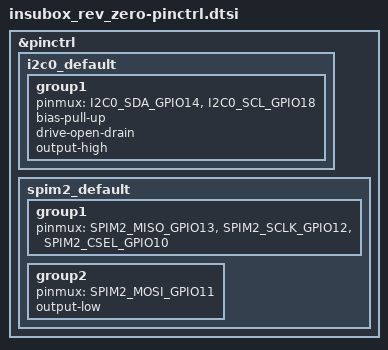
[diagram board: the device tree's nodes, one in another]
/*
 * Copyright (c) 2024 Espressif Systems (Shanghai) Co., Ltd.
 *
 * SPDX-License-Identifier: Apache-2.0
 */

#include <zephyr/dt-bindings/pinctrl/esp-pinctrl-common.h>
#include <dt-bindings/pinctrl/esp32s3-pinctrl.h>
#include <zephyr/dt-bindings/pinctrl/esp32s3-gpio-sigmap.h>

&pinctrl {
	i2c0_default: i2c0_default {
		group1 {
			pinmux = <I2C0_SDA_GPIO14>,
				 <I2C0_SCL_GPIO18>;
			bias-pull-up;
			drive-open-drain;
			output-high;
		};
	};

	spim2_default: spim2_default {
		group1 {
			pinmux = <SPIM2_MISO_GPIO13>,
				 <SPIM2_SCLK_GPIO12>,
				 <SPIM2_CSEL_GPIO10>;
		};
		group2 {
			pinmux = <SPIM2_MOSI_GPIO11>;
			output-low;
		};
	};
};
